AUTOSAR XML (schema 4-2-2)
package /STELLANTIS/EPT/SASWCs
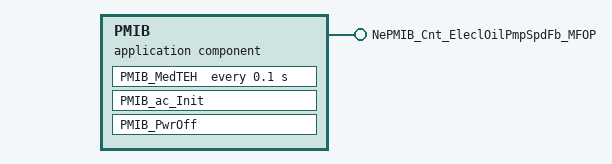
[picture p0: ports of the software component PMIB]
  application sw component type PMIB
    provide port NePMIB_Cnt_EleclOilPmpSpdFb_MFOP: nv-provide-com-spec{ram-block-init-value=0, variable=NePMIB_Cnt_EleclOilPmpSpdFb_MFOP}, provided-interface=NePMIB_Cnt_EleclOilPmpSpdFb_MFOP
    behavior IB_PMIB: data-type-mapping=msADTtoIDTMapping, handle-termination-and-restart=NO-SUPPORT
      timing event Event_MedTEH: start-on-event=PMIB_MedTEH, period=0.1
      init event Event_PMIB_ac_Init: start-on-event=PMIB_ac_Init
      init event Event_PwrOff: start-on-event=PMIB_PwrOff
      runnable PMIB_ac_Init
      runnable PMIB_MedTEH
      runnable PMIB_PwrOff
        data-send-points:
          access OUT_NePMIB_Cnt_EleclOilPmpSpdFb_MFOP_NePMIB_Cnt_EleclOilPmpSpdFb_MFOP: accessed-variable=NePMIB_Cnt_EleclOilPmpSpdFb_MFOP.NePMIB_Cnt_EleclOilPmpSpdFb_MFOP
      variation point proxy Variant_PMIB_EOPSPDFB_Presence: category=CONDITION, condition-access=0
